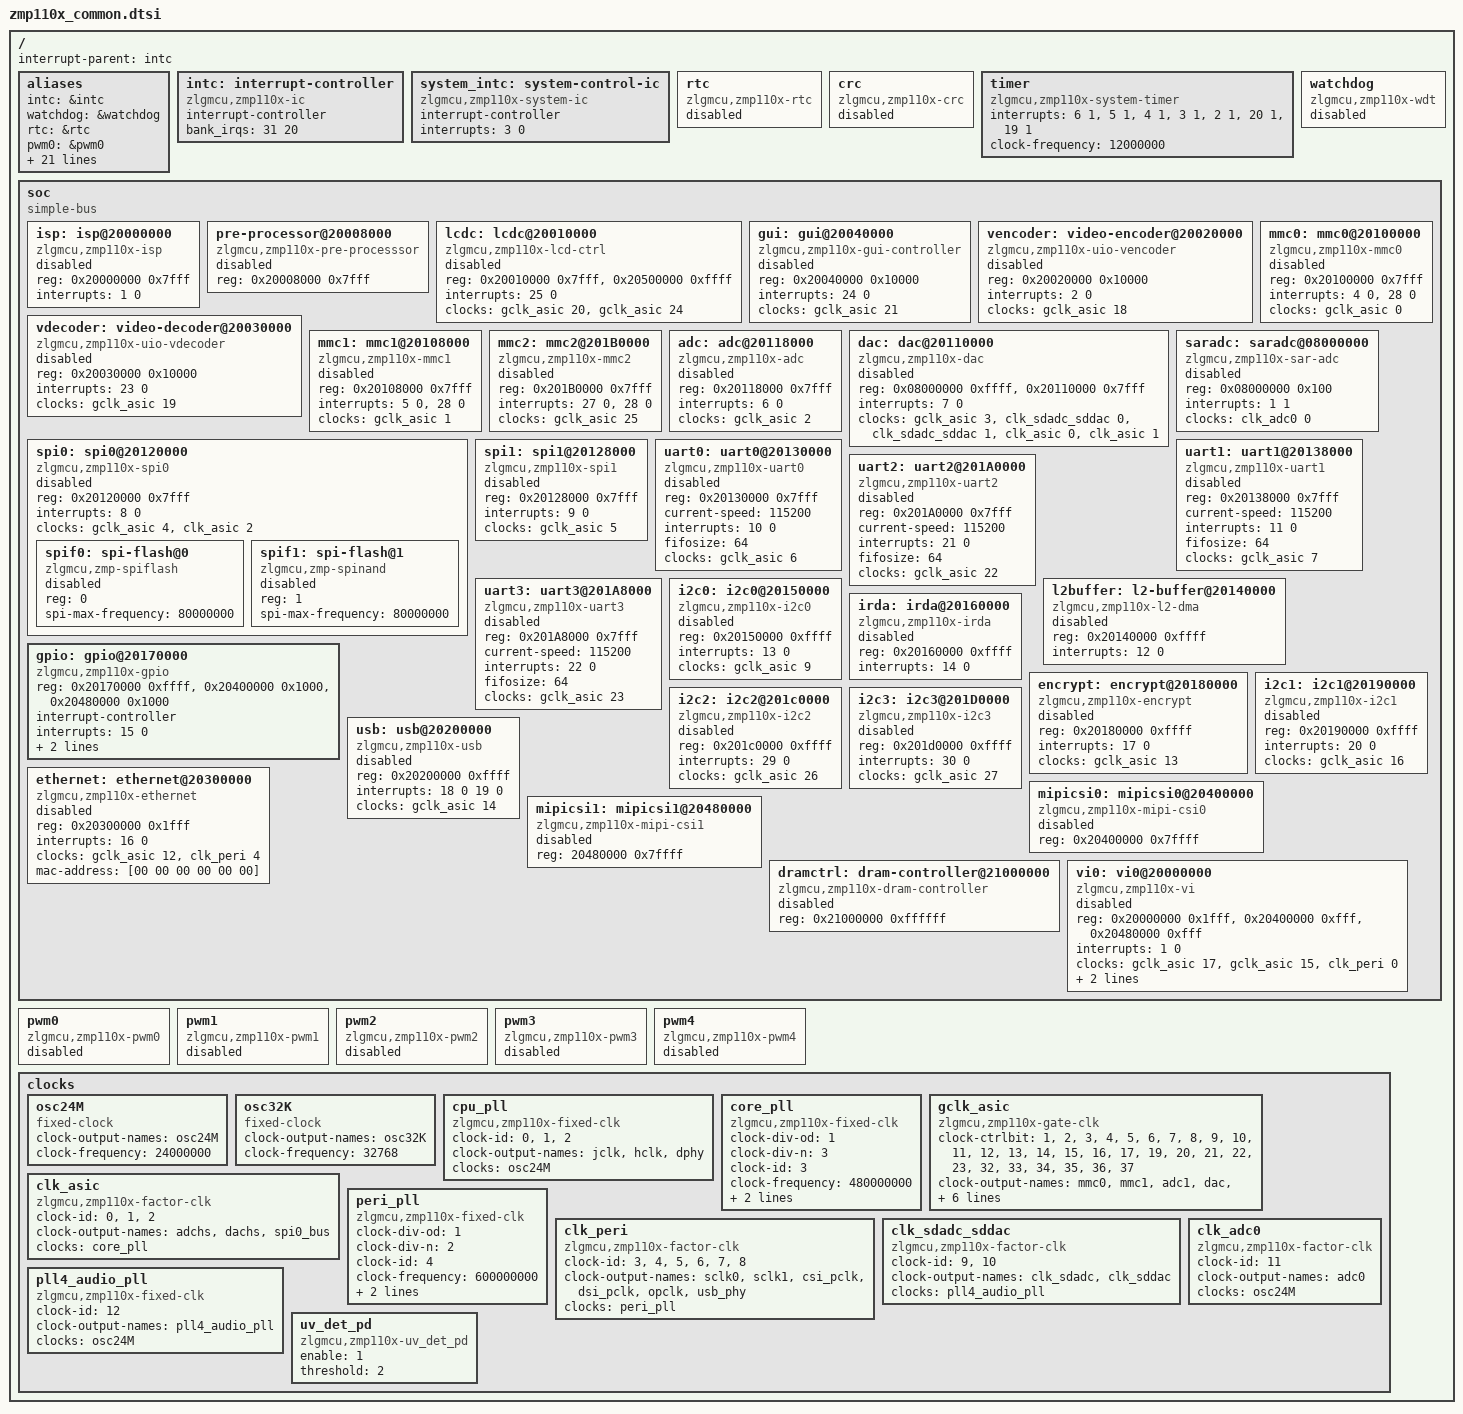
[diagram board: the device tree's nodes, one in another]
/*
 * ZMP110x SoC
 *
 * This program is free software; you can redistribute it and/or modify
 * it under the terms of the GNU General Public License as published by
 * the Free Software Foundation; either version 2 of the License, or
 * (at your option) any later version.
 *
 * This program is distributed in the hope that it will be useful,
 * but WITHOUT ANY WARRANTY; without even the implied warranty of
 * MERCHANTABILITY or FITNESS FOR A PARTICULAR PURPOSE.  See the
 * GNU General Public License for more details.
 */
#include <dt-bindings/gpio/gpio.h>

/ {
    #address-cells = <1>;
    #size-cells = <1>;

    interrupt-parent = <&intc>;

	aliases {
		intc = &intc;
		watchdog = &watchdog;
		rtc = &rtc;
		pwm0 = &pwm0;
		pwm1 = &pwm1;
		pwm2 = &pwm2;
		pwm3 = &pwm3;
		pwm4 = &pwm4;
		gpio = &gpio;
		uart0 = &uart0;
		uart1 = &uart1;
		uart2 = &uart2;
		uart3 = &uart3;
		spi0 = &spi0;
		spi1 = &spi1;
		mmc0 = &mmc0;
		mmc1 = &mmc1;
		mmc2 = &mmc2;
		i2c0 = &i2c0;
		i2c1 = &i2c1;
		i2c2 = &i2c2;
		mipicsi0 = &mipicsi0;
		mipicsi1 = &mipicsi1;
		usb = &usb;		
		ethernet = &ethernet;
	};

    intc: interrupt-controller {
        compatible = "zlgmcu,zmp110x-ic";
        interrupt-controller;
        #interrupt-cells = <2>;
		bank_irqs = <31 20>;
    };

    system_intc: system-control-ic {
        compatible = "zlgmcu,zmp110x-system-ic";
        interrupt-controller;
	    interrupts = <3 0>;
    };

    rtc: rtc {
        compatible = "zlgmcu,zmp110x-rtc";
        status = "disable";
    };

    crc: crc {
        compatible = "zlgmcu,zmp110x-crc";
        status = "disable";
    };

    timer{
        compatible = "zlgmcu,zmp110x-system-timer";
        interrupts = <6 1>,
                     <5 1>,
                     <4 1>,
                     <3 1>,
                     <2 1>,
                     <20 1>,
                     <19 1>;
        clock-frequency = <12000000>;
        status = "okay";
    };

    watchdog: watchdog {
        compatible = "zlgmcu,zmp110x-wdt";
        status = "disable";
    };

	soc: soc {
		compatible = "simple-bus";
		#address-cells = <1>;
		#size-cells = <1>;
		ranges;

        isp: isp@20000000 {
            compatible = "zlgmcu,zmp110x-isp";//TODO
            reg = <0x20000000 0x7fff>;
            interrupts = <1 0>;
            status = "disable";
        };

        pre-processor@20008000 {
            compatible = "zlgmcu,zmp110x-pre-processsor";
            reg = <0x20008000 0x7fff>;
            status = "disable";
        };

        lcdc: lcdc@20010000 {
            compatible = "zlgmcu,zmp110x-lcd-ctrl";
            reg = <0x20010000 0x7fff>, /* lcd ctrl */
                  <0x20500000 0xffff>; /* dsi ctrl */
            interrupts = <25 0>;
            clocks = <&gclk_asic 20>, <&gclk_asic 24>;
            clock-names = "lcdc", "mipi_dsi";
		    status = "disable";
        };

		gui: gui@20040000 {
			compatible = "zlgmcu,zmp110x-gui-controller";
			reg = <0x20040000 0x10000>;
			interrupts = <24 0>;
			clocks = <&gclk_asic 21>;
			status = "disable";
		};

        vencoder: video-encoder@20020000 {
            compatible = "zlgmcu,zmp110x-uio-vencoder";
            reg = <0x20020000 0x10000>;
            interrupts = <2 0>;
            clocks = <&gclk_asic 18>;
            status = "disable";
        };

        vdecoder: video-decoder@20030000 {
            compatible = "zlgmcu,zmp110x-uio-vdecoder";
            reg = <0x20030000 0x10000>;
            interrupts = <23 0>;
            clocks = <&gclk_asic 19>;
            status = "disable";
        };

		mmc0: mmc0@20100000 {
            compatible = "zlgmcu,zmp110x-mmc0";
            reg = <0x20100000 0x7fff>;
            interrupts = <4 0>,<28 0>;
			clocks = <&gclk_asic 0>;
            status = "disable";
        };

        mmc1: mmc1@20108000 {
            compatible = "zlgmcu,zmp110x-mmc1";
            reg = <0x20108000 0x7fff>;
            interrupts = <5 0>, <28 0>;
			clocks = <&gclk_asic 1>;
            status = "disable";
        };

        mmc2: mmc2@201B0000 {
            compatible = "zlgmcu,zmp110x-mmc2";
            reg = <0x201B0000 0x7fff>;
            interrupts = <27 0>,<28 0>;
			clocks = <&gclk_asic 25>;
            status = "disable";
        };

        adc: adc@20118000 {
            compatible = "zlgmcu,zmp110x-adc";
            reg = <0x20118000 0x7fff>;
            interrupts = <6 0>;
            clocks = <&gclk_asic 2>;
            status = "disable";
        };

        dac: dac@20110000 {
            compatible = "zlgmcu,zmp110x-dac";
            reg = <0x08000000 0xffff>,
			      <0x20110000 0x7fff>;
            interrupts = <7 0>;
            clocks = <&gclk_asic 3>,
            <&clk_sdadc_sddac 0>,
            <&clk_sdadc_sddac 1>,
            <&clk_asic 0>,	//adc hs clk
            <&clk_asic 1>;	//dac hs clk
            clock-names = "gate_dac",
           "clk_sdadc",
           "clk_sddac",
           "adchs",
           "dachs";
           status = "disable";
        };
        
        saradc: saradc@08000000 {
            compatible = "zlgmcu,zmp110x-sar-adc";
            reg = <0x08000000 0x100>;
            interrupts = <1 1>;
	        clocks = <&clk_adc0 0>;
            status = "disable";
        };
        
        spi0: spi0@20120000 {
            compatible = "zlgmcu,zmp110x-spi0";
            reg = <0x20120000 0x7fff>;
            interrupts = <8 0>;
            clocks = <&gclk_asic 4>, <&clk_asic 2>;
            clock-names = "spi0", "spi0_bus";

            #address-cells = <1>;
            #size-cells = <0>;
            status = "disable";

			spif0:spi-flash@0 {
			    compatible = "zlgmcu,zmp-spiflash";
				reg = <0>; /* Chip select 0 */
				spi-max-frequency = <80000000>;
				status = "disable";
				#address-cells = <1>;
            	#size-cells = <0>;
			};

			spif1:spi-flash@1 {
			   compatible = "zlgmcu,zmp-spinand";
			   reg = <1>; /* Chip select 1 */
			   spi-max-frequency = <80000000>;
			   ///status = "okay";
			   status = "disable";
			};
        };

        spi1: spi1@20128000 {
            compatible = "zlgmcu,zmp110x-spi1";
            reg = <0x20128000 0x7fff>;
            interrupts = <9 0>;
            clocks = <&gclk_asic 5>;

            #address-cells = <1>;
            #size-cells = <0>;
            status = "disable";
        };

        uart0: uart0@20130000 {
            compatible = "zlgmcu,zmp110x-uart0";
            reg = <0x20130000 0x7fff>;
            current-speed = <115200>;
            interrupts = <10 0>;
            fifosize = <64>;
            clocks = <&gclk_asic 6>;
            status = "disable";
        };

        uart1: uart1@20138000 {
            compatible = "zlgmcu,zmp110x-uart1";
            reg = <0x20138000 0x7fff>;
            current-speed = <115200>;
            interrupts = <11 0>;
            fifosize = <64>;
            clocks = <&gclk_asic 7>;
            status = "disable";
        };

        uart2: uart2@201A0000 {
            compatible = "zlgmcu,zmp110x-uart2";
            reg = <0x201A0000 0x7fff>;
            current-speed = <115200>;
            interrupts = <21 0>;
            fifosize = <64>;
            clocks = <&gclk_asic 22>;
            status = "disable";
        };

        uart3: uart3@201A8000 {
            compatible = "zlgmcu,zmp110x-uart3";
            reg = <0x201A8000 0x7fff>;
            current-speed = <115200>;
            interrupts = <22 0>;
            fifosize = <64>;
            clocks = <&gclk_asic 23>;
            status = "disable";
        };
        
        
        l2buffer: l2-buffer@20140000 {
            compatible = "zlgmcu,zmp110x-l2-dma";
            reg = <0x20140000 0xffff>;
            interrupts = <12 0>;
            status = "disable";
        };

        i2c0: i2c0@20150000 {
            compatible = "zlgmcu,zmp110x-i2c0";
            reg = <0x20150000 0xffff>;
            interrupts = <13 0>;
            clocks = <&gclk_asic 9>;

            status = "disable";
        };

        irda: irda@20160000 {
            compatible = "zlgmcu,zmp110x-irda";
            reg = <0x20160000 0xffff>;
            interrupts = <14 0>;
            status = "disable";
        };

        gpio: gpio@20170000 {
            compatible = "zlgmcu,zmp110x-gpio";
            reg = <0x20170000 0xffff>,
            <0x20400000 0x1000>,	/* mipi0 */
            <0x20480000 0x1000>;	/* mipi1 */

            interrupt-controller;
            #interrupt-cells = <2>;
            interrupts = <15 0>;
            clocks = <&gclk_asic 12>;

            gpio-controller;
            #gpio-cells = <2>;
            status = "okay";
        };
//crypto.ko
        encrypt: encrypt@20180000 {
            compatible = "zlgmcu,zmp110x-encrypt";
            reg = <0x20180000 0xffff>;
            interrupts = <17 0>;
            clocks = <&gclk_asic 13>;
            status = "disable";
        };

        i2c1: i2c1@20190000 {
            compatible = "zlgmcu,zmp110x-i2c1";
            reg = <0x20190000 0xffff>;
            interrupts = <20 0>;
            clocks = <&gclk_asic 16>;

            status = "disable";
        };
        
       i2c2: i2c2@201c0000 {
            compatible = "zlgmcu,zmp110x-i2c2";
            reg = <0x201c0000 0xffff>;
            interrupts = <29 0>;
            clocks = <&gclk_asic 26>;

            #address-cells = <1>;
	        #size-cells = <0>;
            status = "disable";
        };

        i2c3: i2c3@201D0000 {
            compatible = "zlgmcu,zmp110x-i2c3";
            reg = <0x201d0000 0xffff>;
            interrupts = <30 0>;
            clocks = <&gclk_asic 27>;
 
            #address-cells = <1>;
            #size-cells = <0>;
            status = "disable";
        };

        usb: usb@20200000 {
            compatible = "zlgmcu,zmp110x-usb";
            reg = <0x20200000 0xffff>;
            interrupts = <18 0
                          19 0>;
            clocks = <&gclk_asic 14>;
            status = "disable";
        };

        ethernet: ethernet@20300000 {
            compatible = "zlgmcu,zmp110x-ethernet";
            reg = <0x20300000 0x1fff>;
            interrupts = <16 0>;
            clock-names = "ethernet", "50M";
            clocks = <&gclk_asic 12>, <&clk_peri 4>;
			mac-address = [00 00 00 00 00 00];
            status = "disable";
        };

        mipicsi0: mipicsi0@20400000 {
            compatible = "zlgmcu,zmp110x-mipi-csi0";
            reg = <0x20400000 0x7ffff>;
            status = "disable";
        };

        mipicsi1: mipicsi1@20480000 {
            compatible = "zlgmcu,zmp110x-mipi-csi1";
            reg = <20480000 0x7ffff>;
            status = "disable";
        };

        dramctrl:dram-controller@21000000 {
            compatible = "zlgmcu,zmp110x-dram-controller";
            reg = <0x21000000 0xffffff>;
            status = "disable";
        };

        vi0: vi0@20000000 {
            compatible = "zlgmcu,zmp110x-vi";
            reg = <0x20000000 0x1fff>,	/*isp*/
                  <0x20400000 0xfff>,	/*mipicsi0*/
                  <0x20480000 0xfff>;	/*mipicsi1*/
            interrupts = <1 0>;
            clocks = <&gclk_asic 17>, <&gclk_asic 15>, <&clk_peri 0>;
            clock-names = "isp_clk", "mipi_csi_clk", "csi_sclk";
            clock-frequency_isp_clk = <24000000>;
			/*
				interface: 0-dvp, 1-mipi1lane, 2-mipi2lane
			*/
			interface = <0>;

		    status = "disable";
        };
	};

	pwm0: pwm0 {
		compatible = "zlgmcu,zmp110x-pwm0";
		status = "disable";
	};

	pwm1: pwm1 {
		compatible = "zlgmcu,zmp110x-pwm1";
		status = "disable";
	};

	pwm2: pwm2 {
		compatible = "zlgmcu,zmp110x-pwm2";
		status = "disable";
	};

	pwm3: pwm3 {
		compatible = "zlgmcu,zmp110x-pwm3";
		status = "disable";
	};

    pwm4: pwm4 {
		compatible = "zlgmcu,zmp110x-pwm4";
		status = "disable";
	};

    clocks {
        osc24M: osc24M {
            compatible = "fixed-clock";
            #clock-cells = <0>;
            clock-output-names = "osc24M";
            clock-frequency = <24000000>;
        };

        osc32K {
            compatible = "fixed-clock";
            #clock-cells = <0>;
            clock-output-names = "osc32K";
            clock-frequency = <32768>;
        };

        /* this clocks are configed in boot setting, can't be configed in kernel */
        /* this node is only for get cpu and mem clk in kernel */
        cpu_pll {
            compatible = "zlgmcu,zmp110x-fixed-clk";
            #clock-cells = <1>;
            clock-id = <0>, <1>, <2>;
        	clock-output-names = "jclk", "hclk", "dphy";
            clocks = <&osc24M>;
        };

        core_pll: core_pll {
            compatible = "zlgmcu,zmp110x-fixed-clk";
            #clock-cells = <0>;
            clock-div-od = <1>;
            clock-div-n = <3>;
            clock-id = <3>;
        	clock-frequency = <480000000>;
            clock-output-names = "core_pll";
            clocks = <&osc24M>;
        };

        gclk_asic:gclk_asic {
        	compatible = "zlgmcu,zmp110x-gate-clk";
        	#clock-cells = <1>;
            clock-ctrlbit = <1>, <2>, <3>,
                            <4>, <5>, <6>,
                            <7>, <8>, <9>,
                            <10>, <11>, <12>,
                            <13>, <14>, <15>,
                            <16>, <17>, <19>,
                            <20>, <21>, <22>,
                            <23>, <32>, <33>,
                            <34>, <35>, <36>,
                            <37>;
            clock-output-names = "mmc0", "mmc1", "adc1",
                                 "dac", "spi0", "spi1",
                                 "uart0", "uart1", "l2buffer",
                                 "i2c0", "irda", "gpio",
                                 "ethernet", "encrypt", "usb-otg",
                                 "mipi_csi", "i2c1", "isp",
                                 "vencoder","vdecoder","lcdc",
                                 "gui", "uart2", "uart3", 
                                 "mipi_dsi", "mmc2", "i2c2",
                                 "i2c3";
            clocks = <&core_pll>;
        };

        clk_asic: clk_asic {
        	compatible = "zlgmcu,zmp110x-factor-clk";
        	#clock-cells = <1>;
        	clock-id = <0>, <1>, <2>;
        	clock-output-names = "adchs", "dachs", "spi0_bus";
            clocks = <&core_pll>;
        };

    	/*config this clock in uboot*/
    	peri_pll: peri_pll {
            compatible = "zlgmcu,zmp110x-fixed-clk";
            #clock-cells = <0>;
            clock-div-od = <1>;
            clock-div-n = <2>;
        	clock-id = <4>;
        	clock-frequency = <600000000>;
        	clock-output-names = "peri_pll";
            clocks = <&osc24M>;
        };

        clk_peri: clk_peri {
        	compatible = "zlgmcu,zmp110x-factor-clk";
        	#clock-cells = <1>;
        	clock-id = <3>, <4>, <5>, <6>, <7>, <8>;
        	clock-output-names = "sclk0", "sclk1", "csi_pclk", "dsi_pclk", "opclk", "usb_phy";
        	clocks = <&peri_pll>;
        };
        clk_sdadc_sddac: clk_sdadc_sddac{
            compatible = "zlgmcu,zmp110x-factor-clk";
            #clock-cells = <1>;
            clock-id = <9>, <10>;
            clock-output-names = "clk_sdadc", "clk_sddac";
            clocks = <&pll4_audio_pll>;
        };

        clk_adc0: clk_adc0 {
        	compatible = "zlgmcu,zmp110x-factor-clk";
        	#clock-cells = <1>;
        	clock-id = <11>;
        	clock-output-names = "adc0";
        	clocks = <&osc24M>;
        };

        pll4_audio_pll: pll4_audio_pll {
            compatible = "zlgmcu,zmp110x-fixed-clk";
            #clock-cells = <0>;
            clock-id = <12>;
            clock-output-names = "pll4_audio_pll";
            clocks = <&osc24M>;
		};

       uv_det_pd:uv_det_pd {
            compatible = "zlgmcu,zmp110x-uv_det_pd";
            /*
            under_voltage_detection

            enable:
            0: disable under voltage detection
            1: enable under voltage detection

            threshold:
            0: reset when VDDIO drops below 2.48V,
                and the reset will be deasserted when VDDIO reaches 2.68V
            1: reset when VDDIO drops below 2.65V,
                and the reset will be deasserted when VDDIO reaches 2.86V
            2: reset when VDDIO drops below 2.72V,
                and the reset will be deasserted when VDDIO reaches 2.93V
            */
            enable = <1>;
            threshold = <2>;
            status = "okay";
        };
    };
};
